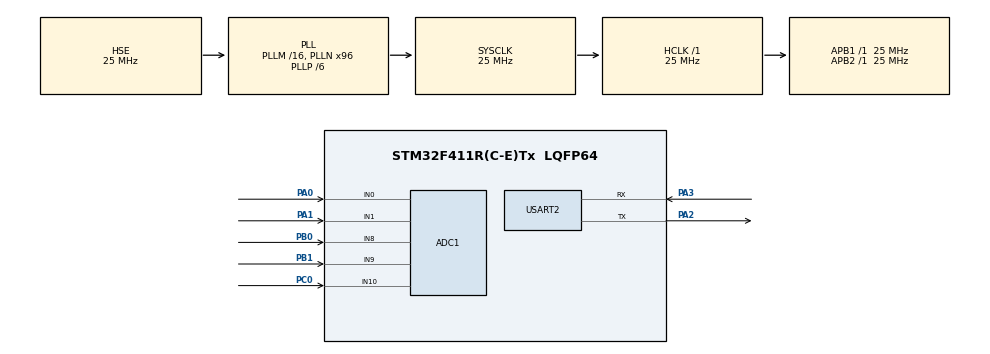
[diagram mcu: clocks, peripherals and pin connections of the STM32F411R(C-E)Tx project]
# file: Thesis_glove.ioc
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ADC1.Channel-0\#ChannelRegularConversion=ADC_CHANNEL_0
ADC1.ContinuousConvMode=ENABLE
ADC1.DMAContinuousRequests=ENABLE
ADC1.EnableAnalogWatchDog=true
ADC1.InjNumberOfConversion=0
ADC1.NbrOfConversionFlag=1
ADC1.Rank-0\#ChannelRegularConversion=1
ADC1.SamplingTime-0\#ChannelRegularConversion=ADC_SAMPLETIME_3CYCLES
ADC1.master=1
Dma.ADC1.0.Direction=DMA_PERIPH_TO_MEMORY
Dma.ADC1.0.FIFOMode=DMA_FIFOMODE_ENABLE
Dma.ADC1.0.FIFOThreshold=DMA_FIFO_THRESHOLD_FULL
Dma.ADC1.0.Instance=DMA2_Stream0
Dma.ADC1.0.MemBurst=DMA_MBURST_SINGLE
Dma.ADC1.0.MemDataAlignment=DMA_MDATAALIGN_HALFWORD
Dma.ADC1.0.MemInc=DMA_MINC_ENABLE
Dma.ADC1.0.Mode=DMA_CIRCULAR
Dma.ADC1.0.PeriphBurst=DMA_PBURST_SINGLE
Dma.ADC1.0.PeriphDataAlignment=DMA_PDATAALIGN_HALFWORD
Dma.ADC1.0.PeriphInc=DMA_PINC_DISABLE
Dma.ADC1.0.Priority=DMA_PRIORITY_HIGH
Dma.Request0=ADC1
Mcu.Family=STM32F4
Mcu.Name=STM32F411R(C-E)Tx
Mcu.Package=LQFP64
NVIC.ADC_IRQn=true\:0\:0\:false\:false\:true\:true\:true\:true
NVIC.DMA2_Stream0_IRQn=true\:0\:0\:false\:false\:true\:false\:true\:true
NVIC.PriorityGroup=NVIC_PRIORITYGROUP_4
PA0-WKUP.Signal=ADCx_IN0
PA1.Signal=ADCx_IN1
PA2.Mode=Asynchronous
PA2.Signal=USART2_TX
PA3.Mode=Asynchronous
PA3.Signal=USART2_RX
PB0.Signal=ADCx_IN8
PB1.Signal=ADCx_IN9
PC0.Signal=ADCx_IN10
PH0\ -\ OSC_IN.Mode=HSE-External-Oscillator
PH0\ -\ OSC_IN.Signal=RCC_OSC_IN
PH1\ -\ OSC_OUT.Mode=HSE-External-Oscillator
PH1\ -\ OSC_OUT.Signal=RCC_OSC_OUT
ProjectManager.HeapSize=0x200
ProjectManager.StackSize=0x400
ProjectManager.TargetToolchain=STM32CubeIDE
RCC.48MHZClocksFreq_Value=37500000
RCC.AHBFreq_Value=25000000
RCC.APB1Freq_Value=25000000
RCC.APB1TimFreq_Value=25000000
RCC.APB2Freq_Value=25000000
RCC.APB2TimFreq_Value=25000000
RCC.CortexFreq_Value=25000000
RCC.HCLKFreq_Value=25000000
RCC.HSE_VALUE=25000000
RCC.HSI_VALUE=16000000
RCC.LSE_VALUE=32768
RCC.PLLN=96
RCC.PLLP=RCC_PLLP_DIV6
RCC.PLLSourceVirtual=RCC_PLLSOURCE_HSE
RCC.SYSCLKFreq_VALUE=25000000
RCC.SYSCLKSource=RCC_SYSCLKSOURCE_PLLCLK
RCC.VCOOutputFreq_Value=150000000
SH.ADCx_IN0.0=ADC1_IN0,IN0
SH.ADCx_IN1.0=ADC1_IN1,IN1
SH.ADCx_IN10.0=ADC1_IN10,IN10
SH.ADCx_IN8.0=ADC1_IN8,IN8
SH.ADCx_IN9.0=ADC1_IN9,IN9
USART2.VirtualMode=VM_ASYNC
VP_RTC_VS_RTC_Activate.Mode=RTC_Enabled
board=custom

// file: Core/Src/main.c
/* USER CODE BEGIN Header */
/**
  ******************************************************************************
  * @file           : main.c
  * @brief          : Main program body
  ******************************************************************************
  * @attention
  *
  * Copyright (c) 2023 STMicroelectronics.
  * All rights reserved.
  *
  * This software is licensed under terms that can be found in the LICENSE file
  * in the root directory of this software component.
  * If no LICENSE file comes with this software, it is provided AS-IS.
  *
  ******************************************************************************
  */
/* USER CODE END Header */
#include "main.h"
#include "adc.h"
#include "dma.h"
#include "rtc.h"
#include "usart.h"
#include "gpio.h"

void SystemClock_Config(void);

int main(void)
{

  /* MCU Configuration--------------------------------------------------------*/

  /* Reset of all peripherals, Initializes the Flash interface and the Systick. */
  HAL_Init();

  /* USER CODE BEGIN Init */
  static void MPU_Config(void);
  #ifdef __GNUC__
  /* With GCC/RAISONANCE, small printf (option LD Linker->Libraries->Small printf
     set to 'Yes') calls __io_putchar() */
  #define PUTCHAR_PROTOTYPE int __io_putchar(int ch)
  #else
  #define PUTCHAR_PROTOTYPE int fputc(int ch, FILE *f)
  #endif /* __GNUC__ */
  /* USER CODE END Init */

  /* Configure the system clock */
  SystemClock_Config();

  /* Initialize all configured peripherals */
  MX_GPIO_Init();
  MX_DMA_Init();
  MX_ADC1_Init();
  MX_RTC_Init();
  MX_USART2_UART_Init();

  /* Infinite loop */
  while (1)
  {

    /* USER CODE BEGIN 3 */
	  HAL_Delay(500);
	  printf("nigger\n");
  }
  /* USER CODE END 3 */
}

void SystemClock_Config(void)
{
  RCC_OscInitTypeDef RCC_OscInitStruct = {0};
  RCC_ClkInitTypeDef RCC_ClkInitStruct = {0};

  /** Configure the main internal regulator output voltage
  */
  __HAL_RCC_PWR_CLK_ENABLE();
  __HAL_PWR_VOLTAGESCALING_CONFIG(PWR_REGULATOR_VOLTAGE_SCALE1);

  /** Initializes the RCC Oscillators according to the specified parameters
  * in the RCC_OscInitTypeDef structure.
  */
  RCC_OscInitStruct.OscillatorType = RCC_OSCILLATORTYPE_LSI|RCC_OSCILLATORTYPE_HSE;
  RCC_OscInitStruct.HSEState = RCC_HSE_ON;
  RCC_OscInitStruct.LSIState = RCC_LSI_ON;
  RCC_OscInitStruct.PLL.PLLState = RCC_PLL_ON;
  RCC_OscInitStruct.PLL.PLLSource = RCC_PLLSOURCE_HSE;
  RCC_OscInitStruct.PLL.PLLM = 16;
  RCC_OscInitStruct.PLL.PLLN = 96;
  RCC_OscInitStruct.PLL.PLLP = RCC_PLLP_DIV6;
  RCC_OscInitStruct.PLL.PLLQ = 4;
  if (HAL_RCC_OscConfig(&RCC_OscInitStruct) != HAL_OK)
  {
    Error_Handler();
  }

  /** Initializes the CPU, AHB and APB buses clocks
  */
  RCC_ClkInitStruct.ClockType = RCC_CLOCKTYPE_HCLK|RCC_CLOCKTYPE_SYSCLK
                              |RCC_CLOCKTYPE_PCLK1|RCC_CLOCKTYPE_PCLK2;
  RCC_ClkInitStruct.SYSCLKSource = RCC_SYSCLKSOURCE_PLLCLK;
  RCC_ClkInitStruct.AHBCLKDivider = RCC_SYSCLK_DIV1;
  RCC_ClkInitStruct.APB1CLKDivider = RCC_HCLK_DIV1;
  RCC_ClkInitStruct.APB2CLKDivider = RCC_HCLK_DIV1;

  if (HAL_RCC_ClockConfig(&RCC_ClkInitStruct, FLASH_LATENCY_0) != HAL_OK)
  {
    Error_Handler();
  }
}

void Error_Handler(void)
{
  __disable_irq();
  while (1)
  {
  }
}
